AUTOSAR XML (schema 4-2-2)
package /ASW_COM_STD_Package
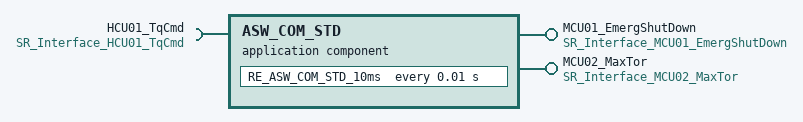
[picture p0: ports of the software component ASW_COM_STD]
  application sw component type ASW_COM_STD
    provide port MCU01_EmergShutDown: provided-interface=SR_Interface_MCU01_EmergShutDown
    provide port MCU02_MaxTor: provided-interface=SR_Interface_MCU02_MaxTor
    require port HCU01_TqCmd: nonqueued-receiver-com-spec{data-element=DE_TqCmd, alive-timeout=0.3}, required-interface=SR_Interface_HCU01_TqCmd
    behavior IB_ASW_COM_STD
      timing event TE_ASW_COM_STD_10ms: start-on-event=RE_ASW_COM_STD_10ms, period=0.01
      runnable RE_ASW_COM_STD_10ms
        data read access RA_HCU01_TqCmd: accessed-variable=HCU01_TqCmd.DE_TqCmd
        data write access WA_MCU01_EmergShutDown: accessed-variable=MCU01_EmergShutDown.DE_EmergShutDown
        data write access WA_MCU02_MaxTor: accessed-variable=MCU02_MaxTor.DE_MaxTor
